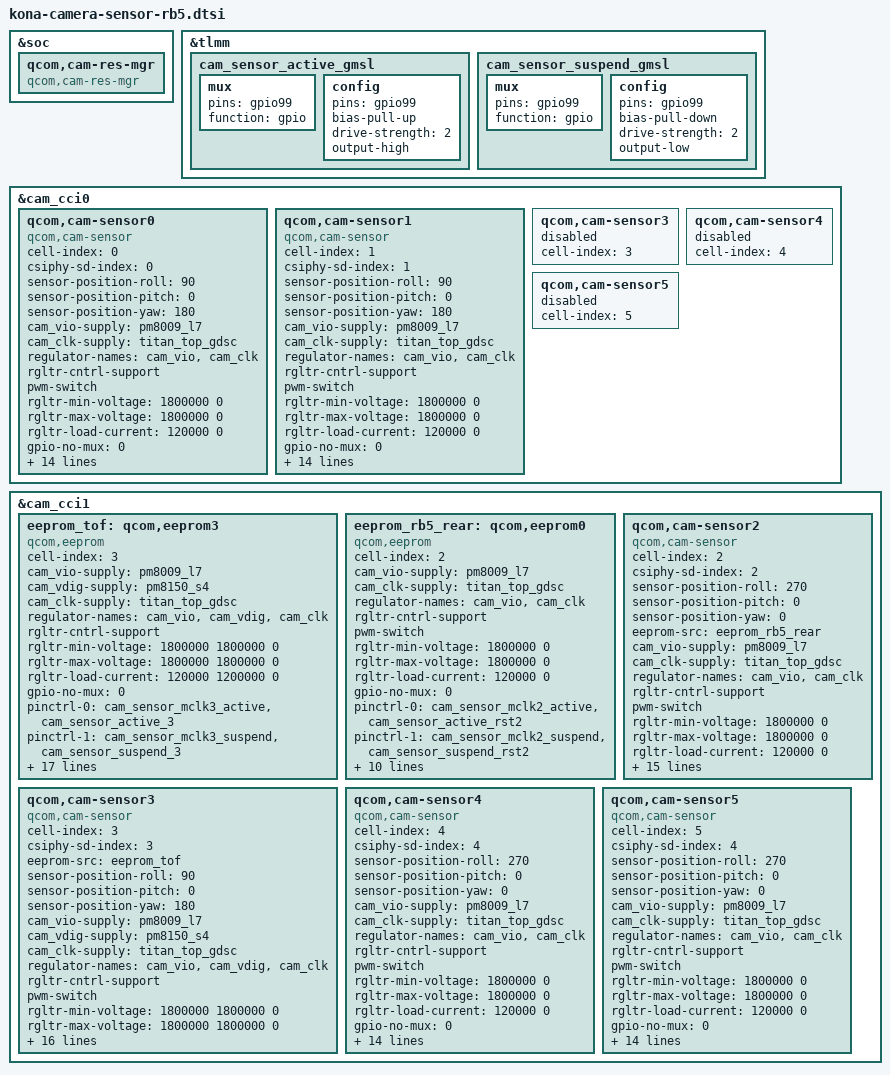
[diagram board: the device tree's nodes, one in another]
&soc {
	qcom,cam-res-mgr {
		compatible = "qcom,cam-res-mgr";
		status = "ok";
	};
};

&tlmm {
	cam_sensor_active_gmsl: cam_sensor_active_gmsl {
		/* RESET */
		mux {
			pins = "gpio99";
			function = "gpio";
		};

		config {
			pins = "gpio99";
			bias-pull-up;
			drive-strength = <2>; /* 2 MA */
			output-high;
		};
	};

	cam_sensor_suspend_gmsl: cam_sensor_suspend_gmsl {
		/* RESET */
		mux {
			pins = "gpio99";
			function = "gpio";
		};

		config {
			pins = "gpio99";
			bias-pull-down; /* PULL DOWN */
			drive-strength = <2>; /* 2 MA */
			output-low;
		};
	};
};

&cam_cci0 {
	qcom,cam-sensor0 {
		cell-index = <0>;
		compatible = "qcom,cam-sensor";
		csiphy-sd-index = <0>;
		sensor-position-roll = <90>;
		sensor-position-pitch = <0>;
		sensor-position-yaw = <180>;
		cam_vio-supply = <&pm8009_l7>;
		cam_clk-supply = <&titan_top_gdsc>;
		regulator-names = "cam_vio", "cam_clk";
		rgltr-cntrl-support;
		pwm-switch;
		rgltr-min-voltage = <1800000 0>;
		rgltr-max-voltage = <1800000 0>;
		rgltr-load-current = <120000 0>;
		gpio-no-mux = <0>;
		pinctrl-names = "cam_default", "cam_suspend";
		pinctrl-0 = <&cam_sensor_mclk0_active
				&cam_sensor_active_rear>;
		pinctrl-1 = <&cam_sensor_mclk0_suspend
				&cam_sensor_suspend_rear>;
		gpios = <&tlmm 94 0>,
			<&tlmm 93 0>;
		gpio-reset = <1>;
		gpio-req-tbl-num = <0 1>;
		gpio-req-tbl-flags = <1 0>;
		gpio-req-tbl-label = "CAMIF_MCLK0",
					"CAM_RESET0";
		sensor-mode = <0>;
		cci-master = <0>;
		status = "ok";
		clocks = <&clock_camcc CAM_CC_MCLK0_CLK>;
		clock-names = "cam_clk";
		clock-cntl-level = "turbo";
		clock-rates = <24000000>;
	};

	qcom,cam-sensor1 {
		cell-index = <1>;
		compatible = "qcom,cam-sensor";
		csiphy-sd-index = <1>;
		sensor-position-roll = <90>;
		sensor-position-pitch = <0>;
		sensor-position-yaw = <180>;
		cam_vio-supply = <&pm8009_l7>;
		cam_clk-supply = <&titan_top_gdsc>;
		regulator-names = "cam_vio", "cam_clk";
		rgltr-cntrl-support;
		pwm-switch;
		rgltr-min-voltage = <1800000 0>;
		rgltr-max-voltage = <1800000 0>;
		rgltr-load-current = <120000 0>;
		gpio-no-mux = <0>;
		pinctrl-names = "cam_default", "cam_suspend";
		pinctrl-0 = <&cam_sensor_mclk1_active
				&cam_sensor_active_rear_aux>;
		pinctrl-1 = <&cam_sensor_mclk1_suspend
				&cam_sensor_suspend_rear_aux>;
		gpios = <&tlmm 95 0>,
			<&tlmm 92 0>;
		gpio-reset = <1>;
		gpio-req-tbl-num = <0 1>;
		gpio-req-tbl-flags = <1 0>;
		gpio-req-tbl-label = "CAMIF_MCLK0",
					"CAM_RESET0";
		sensor-mode = <0>;
		cci-master = <1>;
		status = "ok";
		clocks = <&clock_camcc CAM_CC_MCLK1_CLK>;
		clock-names = "cam_clk";
		clock-cntl-level = "turbo";
		clock-rates = <24000000>;
	};

	qcom,cam-sensor3 {
		cell-index = <3>;
		status = "disable";
	};

	qcom,cam-sensor4 {
		cell-index = <4>;
		status = "disable";
	};

	qcom,cam-sensor5 {
		cell-index = <5>;
		status = "disable";
	};
};

&cam_cci1 {
	eeprom_tof: qcom,eeprom3 {
		cell-index = <3>;
		compatible = "qcom,eeprom";
		cam_vio-supply = <&pm8009_l7>;
		cam_vdig-supply = <&pm8150_s4>;
		cam_clk-supply = <&titan_top_gdsc>;
		regulator-names = "cam_vio", "cam_vdig",
			"cam_clk";
		rgltr-cntrl-support;
		rgltr-min-voltage = <1800000 1800000 0>;
		rgltr-max-voltage = <1800000 1800000 0>;
		rgltr-load-current = <120000 1200000 0>;
		gpio-no-mux = <0>;
		pinctrl-names = "cam_default", "cam_suspend";
		pinctrl-0 = <&cam_sensor_mclk3_active
			&cam_sensor_active_3>;
		pinctrl-1 = <&cam_sensor_mclk3_suspend
			&cam_sensor_suspend_3>;
		gpios = <&tlmm 97 0>,
			<&tlmm 144 0>;
		gpio-reset = <1>;
		gpio-req-tbl-num = <0 1>;
		gpio-req-tbl-flags = <1 0>;
		gpio-req-tbl-label = "CAMIF_MCLK3",
			"CAM_RESET3";
		sensor-position = <1>;
		sensor-mode = <0>;
		cci-master = <1>;
		qcom,cam-power-seq-type ="cam_reset","cam_vio","cam_clk","cam_reset";
		qcom,cam-power-seq-val = "cam_reset","cam_vio"
			,"cam_mclk","cam_reset";
		qcom,cam-power-seq-cfg-val = <0 1 24000000 1>;
		qcom,cam-power-seq-delay = <1 0 1 18>;
		status = "ok";
		clocks = <&clock_camcc CAM_CC_MCLK3_CLK>;
		clock-names = "cam_clk";
		clock-cntl-level = "turbo";
		clock-rates = <24000000>;
	};

	eeprom_rb5_rear: qcom,eeprom0 {
		cell-index = <2>;
		compatible = "qcom,eeprom";
		cam_vio-supply = <&pm8009_l7>;
		cam_clk-supply = <&titan_top_gdsc>;
		regulator-names = "cam_vio", "cam_clk";
		rgltr-cntrl-support;
		pwm-switch;
		rgltr-min-voltage = <1800000 0>;
		rgltr-max-voltage = <1800000 0>;
		rgltr-load-current = <120000 0>;
		gpio-no-mux = <0>;
		pinctrl-names = "cam_default", "cam_suspend";
		pinctrl-0 = <&cam_sensor_mclk2_active
				 &cam_sensor_active_rst2>;
		pinctrl-1 = <&cam_sensor_mclk2_suspend
				 &cam_sensor_suspend_rst2>;
		gpios = <&tlmm 96 0>,
			<&tlmm 78 0>;
		gpio-reset = <1>;
		gpio-req-tbl-num = <0 1>;
		gpio-req-tbl-flags = <1 0>;
		gpio-req-tbl-label = "CAMIF_MCLK2",
					"CAM_RESET2";
		sensor-mode = <0>;
		cci-master = <0>;
		status = "ok";
		clocks = <&clock_camcc CAM_CC_MCLK2_CLK>;
		clock-names = "cam_clk";
		clock-cntl-level = "turbo";
		clock-rates = <24000000>;
	};

	qcom,cam-sensor2 {
		cell-index = <2>;
		compatible = "qcom,cam-sensor";
		csiphy-sd-index = <2>;
		sensor-position-roll = <270>;
		sensor-position-pitch = <0>;
		sensor-position-yaw = <0>;
		eeprom-src = <&eeprom_rb5_rear>;
		cam_vio-supply = <&pm8009_l7>;
		cam_clk-supply = <&titan_top_gdsc>;
		regulator-names = "cam_vio", "cam_clk";
		rgltr-cntrl-support;
		pwm-switch;
		rgltr-min-voltage = <1800000 0>;
		rgltr-max-voltage = <1800000 0>;
		rgltr-load-current = <120000 0>;
		gpio-no-mux = <0>;
		pinctrl-names = "cam_default", "cam_suspend";
		pinctrl-0 = <&cam_sensor_mclk2_active
				 &cam_sensor_active_rst2>;
		pinctrl-1 = <&cam_sensor_mclk2_suspend
				 &cam_sensor_suspend_rst2>;
		gpios = <&tlmm 96 0>,
			<&tlmm 78 0>;
		gpio-reset = <1>;
		gpio-req-tbl-num = <0 1>;
		gpio-req-tbl-flags = <1 0>;
		gpio-req-tbl-label = "CAMIF_MCLK2",
					"CAM_RESET2";
		sensor-mode = <0>;
		cci-master = <0>;
		status = "ok";
		clocks = <&clock_camcc CAM_CC_MCLK2_CLK>;
		clock-names = "cam_clk";
		clock-cntl-level = "turbo";
		clock-rates = <24000000>;
	};

	qcom,cam-sensor3 {
		cell-index = <3>;
		compatible = "qcom,cam-sensor";
		csiphy-sd-index = <3>;
		eeprom-src = <&eeprom_tof>;
		sensor-position-roll = <90>;
		sensor-position-pitch = <0>;
		sensor-position-yaw = <180>;
		cam_vio-supply = <&pm8009_l7>;
		cam_vdig-supply = <&pm8150_s4>;
		cam_clk-supply = <&titan_top_gdsc>;
		regulator-names = "cam_vio", "cam_vdig",
			"cam_clk";
		rgltr-cntrl-support;
		pwm-switch;
		rgltr-min-voltage = <1800000 1800000 0>;
		rgltr-max-voltage = <1800000 1800000 0>;
		rgltr-load-current = <120000 1200000 0>;
		gpio-no-mux = <0>;
		pinctrl-names = "cam_default", "cam_suspend";
		pinctrl-0 = <&cam_sensor_mclk3_active
				&cam_sensor_active_rear>;
		pinctrl-1 = <&cam_sensor_mclk3_suspend
				&cam_sensor_suspend_rear>;
		gpios = <&tlmm 97 0>,
			<&tlmm 144 0>;
		gpio-reset = <1>;
		gpio-req-tbl-num = <0 1>;
		gpio-req-tbl-flags = <1 0>;
		gpio-req-tbl-label = "CAMIF_MCLK3",
					"CAM_RESET3";
		sensor-mode = <0>;
		cci-master = <1>;
		status = "ok";
		clocks = <&clock_camcc CAM_CC_MCLK3_CLK>;
		clock-names = "cam_clk";
		clock-cntl-level = "turbo";
		clock-rates = <24000000>;
	};

	qcom,cam-sensor4 {
		cell-index = <4>;
		compatible = "qcom,cam-sensor";
		csiphy-sd-index = <4>;
		sensor-position-roll = <270>;
		sensor-position-pitch = <0>;
		sensor-position-yaw = <0>;
		cam_vio-supply = <&pm8009_l7>;
		cam_clk-supply = <&titan_top_gdsc>;
		regulator-names = "cam_vio", "cam_clk";
		rgltr-cntrl-support;
		pwm-switch;
		rgltr-min-voltage = <1800000 0>;
		rgltr-max-voltage = <1800000 0>;
		rgltr-load-current = <120000 0>;
		gpio-no-mux = <0>;
		pinctrl-names = "cam_default", "cam_suspend";
		pinctrl-0 = <&cam_sensor_mclk2_active
				 &cam_sensor_active_gmsl>;
		pinctrl-1 = <&cam_sensor_mclk2_suspend
				 &cam_sensor_suspend_gmsl>;
		gpios = <&tlmm 94 0>,
			<&tlmm 99 0>;
		gpio-reset = <1>;
		gpio-req-tbl-num = <0 1>;
		gpio-req-tbl-flags = <1 0>;
		gpio-req-tbl-label = "CAMIF_MCLK2",
					"CAM_RESET4";
		sensor-mode = <0>;
		cci-master = <1>;
		status = "ok";
		clocks = <&clock_camcc CAM_CC_MCLK2_CLK>;
		clock-names = "cam_clk";
		clock-cntl-level = "turbo";
		clock-rates = <24000000>;
	};

	qcom,cam-sensor5 {
		cell-index = <5>;
		compatible = "qcom,cam-sensor";
		csiphy-sd-index = <4>;
		sensor-position-roll = <270>;
		sensor-position-pitch = <0>;
		sensor-position-yaw = <0>;
		cam_vio-supply = <&pm8009_l7>;
		cam_clk-supply = <&titan_top_gdsc>;
		regulator-names = "cam_vio", "cam_clk";
		rgltr-cntrl-support;
		pwm-switch;
		rgltr-min-voltage = <1800000 0>;
		rgltr-max-voltage = <1800000 0>;
		rgltr-load-current = <120000 0>;
		gpio-no-mux = <0>;
		pinctrl-names = "cam_default", "cam_suspend";
		pinctrl-0 = <&cam_sensor_mclk2_active
				 &cam_sensor_active_gmsl>;
		pinctrl-1 = <&cam_sensor_mclk2_suspend
				 &cam_sensor_suspend_gmsl>;
		gpios = <&tlmm 94 0>,
			<&tlmm 99 0>;
		gpio-reset = <1>;
		gpio-req-tbl-num = <0 1>;
		gpio-req-tbl-flags = <1 0>;
		gpio-req-tbl-label = "CAMIF_MCLK2",
					"CAM_RESET4";
		sensor-mode = <0>;
		cci-master = <1>;
		status = "ok";
		clocks = <&clock_camcc CAM_CC_MCLK2_CLK>;
		clock-names = "cam_clk";
		clock-cntl-level = "turbo";
		clock-rates = <24000000>;
	};
};
